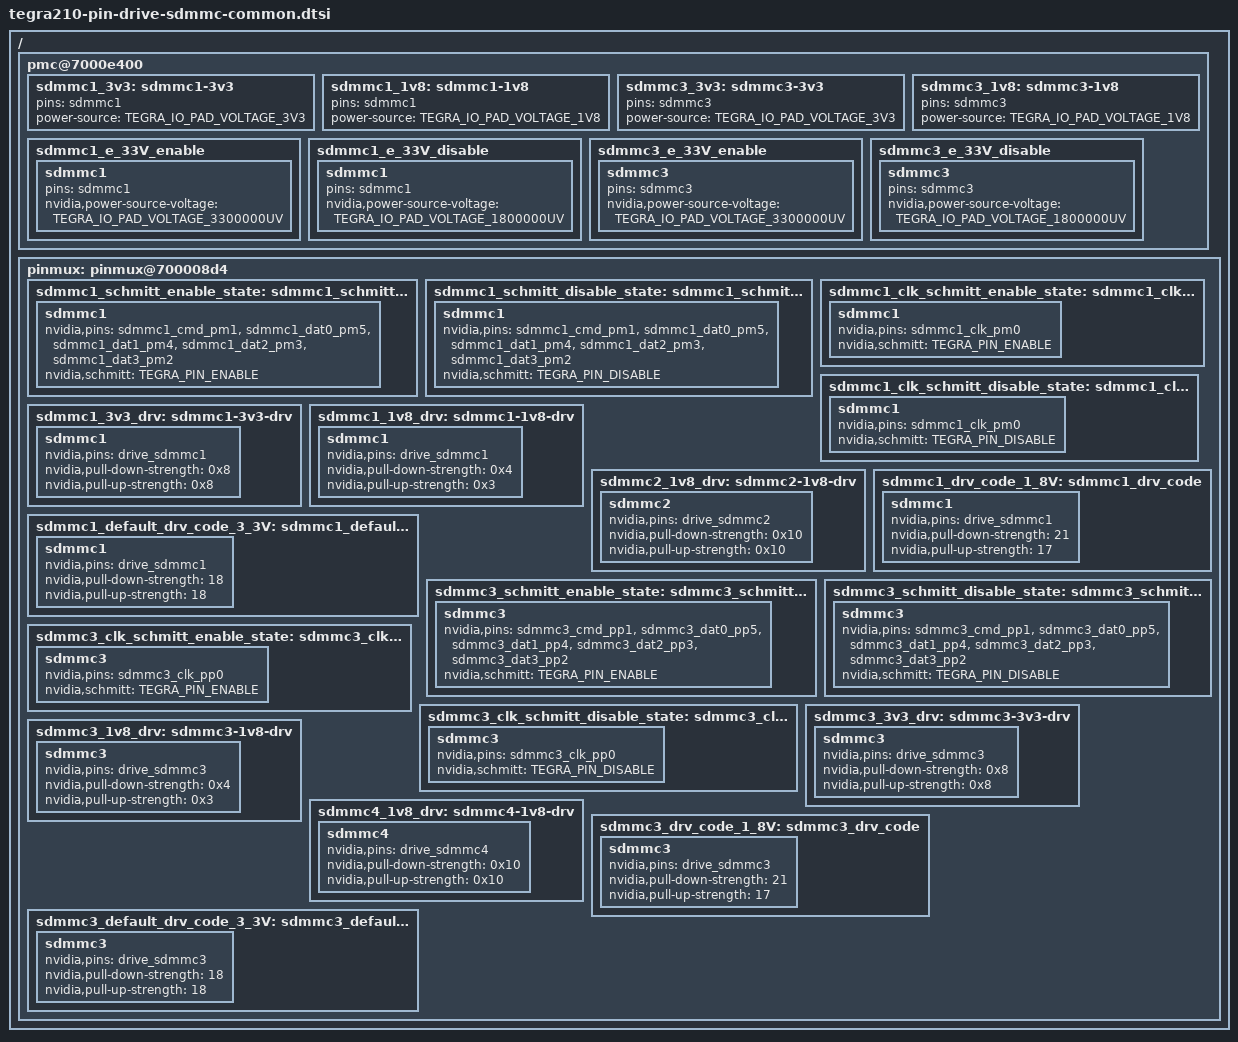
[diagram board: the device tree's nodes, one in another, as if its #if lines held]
/*
 * tegra210-pin-drive-sdmmc-common.dtsi: Common SDMMC pincontrol drive to
 *				configure sdmmc pin's.
 *
 * Copyright (c) 2015-2021, NVIDIA CORPORATION.  All rights reserved.
 *
 * This program is free software; you can redistribute it and/or modify
 * it under the terms of the GNU General Public License as published by
 * the Free Software Foundation; version 2 of the License.
 *
 * This program is distributed in the hope that it will be useful, but WITHOUT
 * ANY WARRANTY; without even the implied warranty of MERCHANTABILITY or
 * FITNESS FOR A PARTICULAR PURPOSE.  See the GNU General Public License for
 * more details.
 *
 */

#include <dt-bindings/pinctrl/pinctrl-tegra-io-pad.h>
#include <dt-bindings/pinctrl/pinctrl-tegra.h>

/ {
	pmc@7000e400 {
#if TEGRA_SDMMC_VERSION >= DT_VERSION_2
		sdmmc1_3v3: sdmmc1-3v3 {
			pins = "sdmmc1";
			power-source = <TEGRA_IO_PAD_VOLTAGE_3V3>;
		};

		sdmmc1_1v8: sdmmc1-1v8 {
			pins = "sdmmc1";
			power-source = <TEGRA_IO_PAD_VOLTAGE_1V8>;
		};

		sdmmc3_3v3: sdmmc3-3v3 {
			pins = "sdmmc3";
			power-source = <TEGRA_IO_PAD_VOLTAGE_3V3>;
		};

		sdmmc3_1v8: sdmmc3-1v8 {
			pins = "sdmmc3";
			power-source = <TEGRA_IO_PAD_VOLTAGE_1V8>;
		};
#endif
		sdmmc1_e_33V_enable: sdmmc1_e_33V_enable {
			sdmmc1 {
				pins = "sdmmc1";
				nvidia,power-source-voltage = <TEGRA_IO_PAD_VOLTAGE_3300000UV>;
			};
		};

		sdmmc1_e_33V_disable: sdmmc1_e_33V_disable {
			sdmmc1 {
				pins = "sdmmc1";
				nvidia,power-source-voltage = <TEGRA_IO_PAD_VOLTAGE_1800000UV>;
			};
		};

		sdmmc3_e_33V_enable: sdmmc3_e_33V_enable {
			sdmmc3 {
				pins = "sdmmc3";
				nvidia,power-source-voltage = <TEGRA_IO_PAD_VOLTAGE_3300000UV>;
			};
		};

		sdmmc3_e_33V_disable: sdmmc3_e_33V_disable {
			sdmmc3 {
				pins = "sdmmc3";
				nvidia,power-source-voltage = <TEGRA_IO_PAD_VOLTAGE_1800000UV>;
			};
		};

	};

	pinmux: pinmux@700008d4 {

		sdmmc1_schmitt_enable_state: sdmmc1_schmitt_enable {
			sdmmc1 {
				nvidia,pins = "sdmmc1_cmd_pm1", "sdmmc1_dat0_pm5", "sdmmc1_dat1_pm4", "sdmmc1_dat2_pm3", "sdmmc1_dat3_pm2";
				nvidia,schmitt = <TEGRA_PIN_ENABLE>;
			};
		};

		sdmmc1_schmitt_disable_state: sdmmc1_schmitt_disable {
			sdmmc1 {
				nvidia,pins = "sdmmc1_cmd_pm1", "sdmmc1_dat0_pm5", "sdmmc1_dat1_pm4", "sdmmc1_dat2_pm3", "sdmmc1_dat3_pm2";
				nvidia,schmitt = <TEGRA_PIN_DISABLE>;
			};
		};

		sdmmc1_clk_schmitt_enable_state: sdmmc1_clk_schmitt_enable {
			sdmmc1 {
				nvidia,pins = "sdmmc1_clk_pm0";
				nvidia,schmitt = <TEGRA_PIN_ENABLE>;
			};
		};

		sdmmc1_clk_schmitt_disable_state: sdmmc1_clk_schmitt_disable {
			sdmmc1 {
				nvidia,pins = "sdmmc1_clk_pm0";
				nvidia,schmitt = <TEGRA_PIN_DISABLE>;
			};
		};

#if TEGRA_SDMMC_VERSION >= DT_VERSION_2
		sdmmc1_3v3_drv: sdmmc1-3v3-drv {
			sdmmc1 {
				nvidia,pins = "drive_sdmmc1";
				nvidia,pull-down-strength = <0x8>;
				nvidia,pull-up-strength = <0x8>;
			};
		};
		sdmmc1_1v8_drv: sdmmc1-1v8-drv {
			sdmmc1 {
				nvidia,pins = "drive_sdmmc1";
				nvidia,pull-down-strength = <0x4>;
				nvidia,pull-up-strength = <0x3>;
			};
		};
		sdmmc2_1v8_drv: sdmmc2-1v8-drv {
			sdmmc2 {
				nvidia,pins = "drive_sdmmc2";
				nvidia,pull-down-strength = <0x10>;
				nvidia,pull-up-strength = <0x10>;
			};
		};
#endif
		sdmmc1_drv_code_1_8V: sdmmc1_drv_code {
			sdmmc1 {
				nvidia,pins = "drive_sdmmc1";
				nvidia,pull-down-strength = <21>;
				nvidia,pull-up-strength = <17>;
			};
		};

		sdmmc1_default_drv_code_3_3V: sdmmc1_default_drv_code {
			sdmmc1 {
				nvidia,pins = "drive_sdmmc1";
				nvidia,pull-down-strength = <18>;
				nvidia,pull-up-strength = <18>;
			};
		};

		sdmmc3_schmitt_enable_state: sdmmc3_schmitt_enable {
			 sdmmc3 {
				 nvidia,pins = "sdmmc3_cmd_pp1", "sdmmc3_dat0_pp5", "sdmmc3_dat1_pp4", "sdmmc3_dat2_pp3", "sdmmc3_dat3_pp2";
				 nvidia,schmitt = <TEGRA_PIN_ENABLE>;
			 };
		 };

		sdmmc3_schmitt_disable_state: sdmmc3_schmitt_disable {
			sdmmc3 {
				nvidia,pins = "sdmmc3_cmd_pp1", "sdmmc3_dat0_pp5", "sdmmc3_dat1_pp4", "sdmmc3_dat2_pp3", "sdmmc3_dat3_pp2";
				nvidia,schmitt = <TEGRA_PIN_DISABLE>;
			};
		};

		sdmmc3_clk_schmitt_enable_state: sdmmc3_clk_schmitt_enable {
			sdmmc3 {
				nvidia,pins = "sdmmc3_clk_pp0";
				nvidia,schmitt = <TEGRA_PIN_ENABLE>;
			};
		};

		sdmmc3_clk_schmitt_disable_state: sdmmc3_clk_schmitt_disable {
			sdmmc3 {
				nvidia,pins = "sdmmc3_clk_pp0";
				nvidia,schmitt = <TEGRA_PIN_DISABLE>;
			};
		};

#if TEGRA_SDMMC_VERSION >= DT_VERSION_2
		sdmmc3_3v3_drv: sdmmc3-3v3-drv {
			sdmmc3 {
				nvidia,pins = "drive_sdmmc3";
				nvidia,pull-down-strength = <0x8>;
				nvidia,pull-up-strength = <0x8>;
			};
		};
		sdmmc3_1v8_drv: sdmmc3-1v8-drv {
			sdmmc3 {
				nvidia,pins = "drive_sdmmc3";
				nvidia,pull-down-strength = <0x4>;
				nvidia,pull-up-strength = <0x3>;
			};
		};
		sdmmc4_1v8_drv: sdmmc4-1v8-drv {
			sdmmc4 {
				nvidia,pins = "drive_sdmmc4";
				nvidia,pull-down-strength = <0x10>;
				nvidia,pull-up-strength = <0x10>;
			};
		};
#endif
		sdmmc3_drv_code_1_8V: sdmmc3_drv_code {
			sdmmc3 {
				nvidia,pins = "drive_sdmmc3";
				nvidia,pull-down-strength = <21>;
				nvidia,pull-up-strength = <17>;
			};
		};

		sdmmc3_default_drv_code_3_3V: sdmmc3_default_drv_code {
			sdmmc3 {
				nvidia,pins = "drive_sdmmc3";
				nvidia,pull-down-strength = <18>;
				nvidia,pull-up-strength = <18>;
			};
		};
	};
};
